# bcm2837_lpa register map
Vendor: BROADCOM; Series: BCM2837; File version: A
CPU: CA72 r0p0, little endian, MPU, FPU, 2 interrupt priority bits
Registers are 32-bit, read-write, reset 0x0 unless marked. A register's access mark holds for its fields unless they carry their own. Offsets are from the block's base; [hi:lo] are bit positions; {n}, {i} and the like mark numbered series; 'fields as' and 'values as' point back to an identical list.

## DMA
Base 0x3F007000
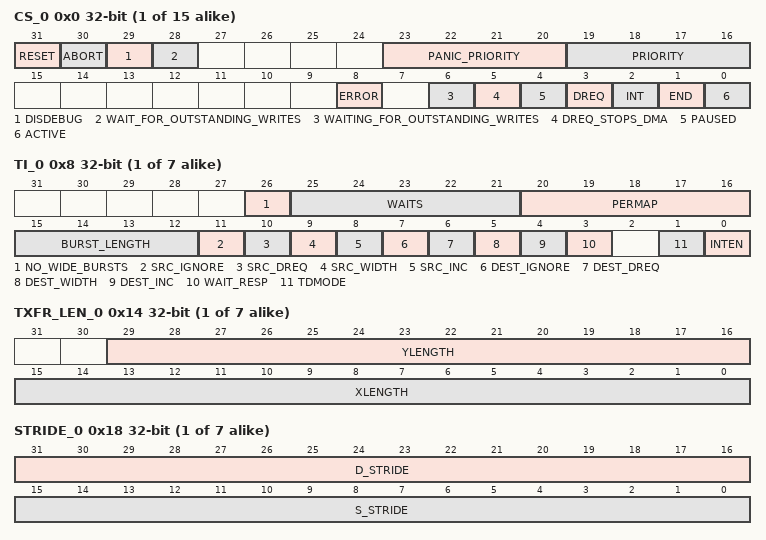
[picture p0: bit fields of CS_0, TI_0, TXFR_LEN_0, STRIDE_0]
{0x0+0x100*i} CS_{i} access per field (i=0..14) — DMA {i} Control And Status register
  [31] RESET wo — DMA Channel Reset
  [30] ABORT wo — Abort DMA
  [29] DISDEBUG rw — Disable debug pause signal
  [28] WAIT_FOR_OUTSTANDING_WRITES rw
  [23:20] PANIC_PRIORITY rw — AXI Panic Priority Level
  [19:16] PRIORITY rw — AXI Priority Level
  [8] ERROR ro — DMA Error
  [6] WAITING_FOR_OUTSTANDING_WRITES ro — DMA is Waiting for the Last Write to be Received
  [5] DREQ_STOPS_DMA ro — DMA Paused by DREQ State
  [4] PAUSED ro — DMA Paused State
  [3] DREQ ro — DREQ State
  [2] INT rw write-1-clears — Interrupt Status
  [1] END rw write-1-clears — DMA End Flag
  [0] ACTIVE rw — Activate the DMA
{0x4+0x100*i} CONBLK_AD_{i} (i=0..14) — DMA Control Block Address register
  [31:0] SCB_ADDR — Control Block Address
{0x8+0x100*i} TI_{i} (i=0..6) — DMA Transfer Information
  [26] NO_WIDE_BURSTS — Dont Do wide writes as a 2 beat burst
  [25:21] WAITS — Add Wait Cycles
  [20:16] PERMAP — Peripheral Mapping
  [15:12] BURST_LENGTH — Burst Transfer Length
  [11] SRC_IGNORE — Ignore Reads
  [10] SRC_DREQ — Control Source Reads with DREQ
  [9] SRC_WIDTH — Source Transfer Width
  [8] SRC_INC — Source Address Increment
  [7] DEST_IGNORE — Ignore Writes
  [6] DEST_DREQ — Control Destination Writes with DREQ
  [5] DEST_WIDTH — Destination Transfer Width
  [4] DEST_INC — Destination Address Increment
  [3] WAIT_RESP — Wait for a Write Response
  [1] TDMODE — 2D Mode
  [0] INTEN — Interrupt Enable
{0xC+0x100*i} SOURCE_AD_{i} (i=0..14) — DMA Source Address
  [31:0] S_ADDR
{0x10+0x100*i} DEST_AD_{i} (i=0..14) — DMA Destination Address
  [31:0] D_ADDR
{0x14+0x100*i} TXFR_LEN_{i} (i=0..6) — DMA Transfer Length.
  [29:16] YLENGTH — When in 2D mode, This is the Y transfer length, indicating how many xlength transfers are performed. When in normal linear mode this becomes the top bits of the XLENGTH
  [15:0] XLENGTH — Transfer Length in bytes
{0x18+0x100*i} STRIDE_{i} (i=0..6) — DMA 2D Stride
  [31:16] D_STRIDE — Destination Stride (2D Mode)
  [15:0] S_STRIDE — Source Stride (2D Mode)
{0x1C+0x100*i} NEXTCONBK_{i} (i=0..14) — DMA Next Control Block Address
  [31:0] ADDR — Address of next CB for chained DMA operations
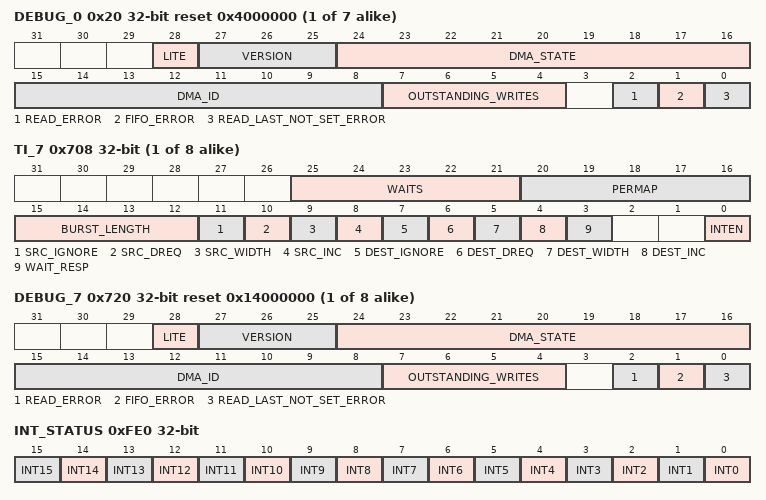
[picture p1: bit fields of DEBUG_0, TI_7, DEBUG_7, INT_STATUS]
{0x20+0x100*i} DEBUG_{i} access per field reset 0x4000000 (i=0..6) — DMA Debug register
  [28] LITE ro — DMA Lite
  [27:25] VERSION ro — DMA Version
  [24:16] DMA_STATE ro — DMA State Machine State
  [15:8] DMA_ID ro
  [7:4] OUTSTANDING_WRITES ro — DMA Outstanding Writes Counter
  [2] READ_ERROR rw — Slave Read Response Error
  [1] FIFO_ERROR rw
  [0] READ_LAST_NOT_SET_ERROR rw
{0x8+0x100*i} TI_{i} (i=7..14) — DMA Transfer Information
  [25:21] WAITS — Add Wait Cycles
  [20:16] PERMAP — Peripheral Mapping
  [15:12] BURST_LENGTH — Burst Transfer Length
  [11] SRC_IGNORE — Ignore Reads
  [10] SRC_DREQ — Control Source Reads with DREQ
  [9] SRC_WIDTH — Source Transfer Width
  [8] SRC_INC — Source Address Increment
  [7] DEST_IGNORE — Ignore Writes
  [6] DEST_DREQ — Control Destination Writes with DREQ
  [5] DEST_WIDTH — Destination Transfer Width
  [4] DEST_INC — Destination Address Increment
  [3] WAIT_RESP — Wait for a Write Response
  [0] INTEN — Interrupt Enable
{0x14+0x100*i} TXFR_LEN_{i} (i=7..14) — DMA Transfer Length.
  [15:0] XLENGTH — Transfer Length in bytes
{0x20+0x100*i} DEBUG_{i} access per field reset 0x14000000 (i=7..14) — DMA lite Debug register
  fields as DEBUG_0
0xFE0 INT_STATUS — Interrupt status of each DMA engine
  [n] INT{n} (n=0..15) — Interrupt status of DMA engine {n}
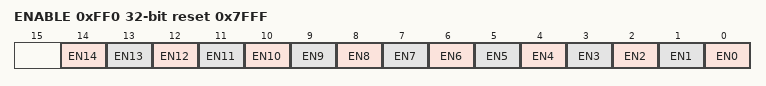
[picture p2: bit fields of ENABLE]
0xFF0 ENABLE reset 0x7FFF — Global enable bits for each channel
  [n] EN{n} (n=0..14) — Enable dma engine {n}
